VERSION ""

NS_ :

BS_:

BU_: CFG MM5_10

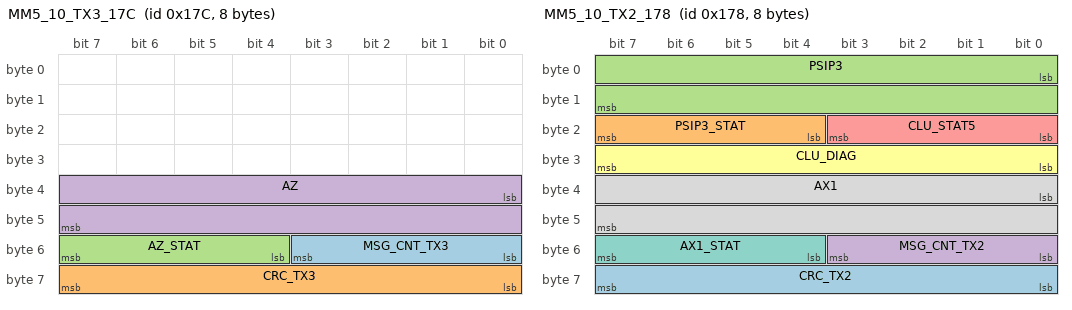
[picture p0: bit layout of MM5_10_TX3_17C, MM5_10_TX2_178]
BO_ 380 MM5_10_TX3_17C: 8 Vector__XXX
 SG_ MSG_CNT_TX3 : 48|4@1+ (1,0) [0|0] "" Vector__XXX
 SG_ CRC_TX3 : 56|8@1+ (1,0) [0|0] "" Vector__XXX
 SG_ AZ_STAT : 52|4@1+ (1,0) [0|0] "" Vector__XXX
 SG_ AZ : 32|16@1+ (0.000127465,-4.1768) [-4.1768|4.1765] "g" Vector__XXX

BO_ 376 MM5_10_TX2_178: 8 Vector__XXX
 SG_ CRC_TX2 : 56|8@1+ (1,0) [0|0] "" Vector__XXX
 SG_ PSIP3_STAT : 20|4@1+ (1,0) [0|0] "" Vector__XXX
 SG_ PSIP3 : 0|16@1+ (0.005,-163.84) [-163.84|163.835] "�/s" Vector__XXX
 SG_ MSG_CNT_TX2 : 48|4@1+ (1,0) [0|0] "" Vector__XXX
 SG_ CLU_STAT5 : 16|4@1+ (1,0) [0|0] "" Vector__XXX
 SG_ CLU_DIAG : 24|8@1+ (1,0) [0|0] "" Vector__XXX
 SG_ AX1_STAT : 52|4@1+ (1,0) [0|0] "" Vector__XXX
 SG_ AX1 : 32|16@1+ (0.000127465,-4.1768) [-4.1768|4.1765] "g" Vector__XXX

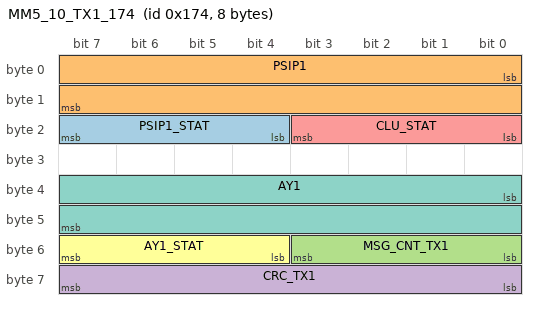
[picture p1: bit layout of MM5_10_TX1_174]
BO_ 372 MM5_10_TX1_174: 8 Vector__XXX
 SG_ PSIP1_STAT : 20|4@1+ (1,0) [0|0] "" Vector__XXX
 SG_ PSIP1 : 0|16@1+ (0.005,-163.84) [-163.84|163.83] "�/s" Vector__XXX
 SG_ MSG_CNT_TX1 : 48|4@1+ (1,0) [0|0] "" Vector__XXX
 SG_ CRC_TX1 : 56|8@1+ (1,0) [0|0] "" Vector__XXX
 SG_ CLU_STAT : 16|4@1+ (1,0) [0|0] "" Vector__XXX
 SG_ AY1_STAT : 52|4@1+ (1,0) [0|0] "" Vector__XXX
 SG_ AY1 : 32|16@1+ (0.000127465,-4.1768) [-4.1768|4.1765] "g" Vector__XXX

BA_DEF_  "BusType" STRING ;
BA_DEF_  "Manufacturer" ENUM  "DBAG","VAG","BMWAG";
BA_DEF_ BO_  "GenMsgSendType" ENUM  "Zyklisch","Ereignisgesteuert","dummy","Auf Anfrage";
BA_DEF_ BO_  "GenMsgSendType2" ENUM  "Zyklisch","Ereignisgesteuert","dummy","Auf Anfrage";
BA_DEF_ BU_  "MessageManagerUsed" ENUM  "no","yes";
BA_DEF_DEF_  "BusType" "CAN";
BA_DEF_DEF_  "Manufacturer" "BMWAG";
BA_DEF_DEF_  "GenMsgSendType" "Zyklisch";
BA_DEF_DEF_  "GenMsgSendType2" "Zyklisch";
BA_DEF_DEF_  "MessageManagerUsed" "yes";
